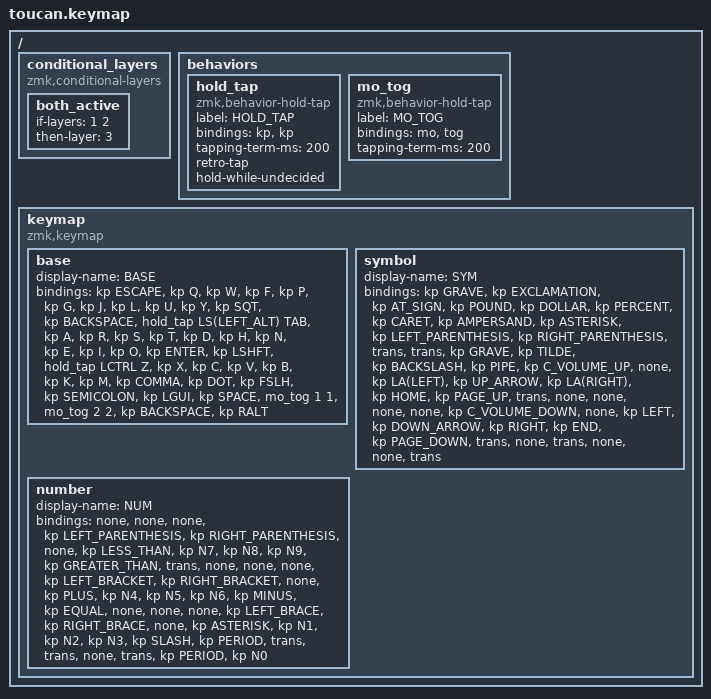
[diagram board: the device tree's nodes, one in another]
#include <behaviors.dtsi>
#include <dt-bindings/zmk/keys.h>

#define BASE 0
#define NAV  1
#define SYM  2
#define ADJ  3

/ {
    conditional_layers {
        compatible = "zmk,conditional-layers";

        both_active {
            if-layers = <1 2>;
            then-layer = <3>;
        };
    };

    behaviors {
        hold_tap: hold_tap {
            compatible = "zmk,behavior-hold-tap";
            label = "HOLD_TAP";
            bindings = <&kp>, <&kp>;

            #binding-cells = <2>;
            tapping-term-ms = <200>;
            retro-tap;
            hold-while-undecided;
        };

        mo_tog: mo_tog {
            compatible = "zmk,behavior-hold-tap";
            label = "MO_TOG";
            bindings = <&mo>, <&tog>;

            #binding-cells = <2>;
            tapping-term-ms = <200>;
        };
    };

    keymap {
        compatible = "zmk,keymap";

        base {
            display-name = "BASE";
            bindings = <
&kp ESCAPE  &kp Q  &kp W  &kp F  &kp P  &kp G  &kp J  &kp L  &kp U  &kp Y  &kp SQT  &kp BACKSPACE  &hold_tap LS(LEFT_ALT) TAB  &kp A  &kp R  &kp S  &kp T  &kp D  &kp H  &kp N  &kp E  &kp I  &kp O  &kp ENTER  &kp LSHFT  &hold_tap LCTRL Z  &kp X  &kp C  &kp V  &kp B  &kp K  &kp M  &kp COMMA  &kp DOT  &kp FSLH  &kp SEMICOLON  &kp LGUI  &kp SPACE  &mo_tog 1 1  &mo_tog 2 2  &kp BACKSPACE  &kp RALT
            >;
        };

        symbol {
            display-name = "SYM";
            bindings = <
&kp GRAVE  &kp EXCLAMATION  &kp AT_SIGN  &kp POUND  &kp DOLLAR  &kp PERCENT  &kp CARET  &kp AMPERSAND  &kp ASTERISK  &kp LEFT_PARENTHESIS  &kp RIGHT_PARENTHESIS  &trans  &trans  &kp GRAVE  &kp TILDE  &kp BACKSLASH  &kp PIPE  &kp C_VOLUME_UP  &none  &kp LA(LEFT)  &kp UP_ARROW  &kp LA(RIGHT)  &kp HOME  &kp PAGE_UP  &trans  &none  &none  &none  &none  &kp C_VOLUME_DOWN  &none  &kp LEFT  &kp DOWN_ARROW  &kp RIGHT  &kp END  &kp PAGE_DOWN  &trans  &none  &trans  &none  &none  &trans
            >;
        };

        number {
            display-name = "NUM";
            bindings = <
&none  &none  &none  &kp LEFT_PARENTHESIS  &kp RIGHT_PARENTHESIS  &none  &kp LESS_THAN  &kp N7  &kp N8  &kp N9  &kp GREATER_THAN  &trans  &none  &none  &none  &kp LEFT_BRACKET  &kp RIGHT_BRACKET  &none  &kp PLUS  &kp N4  &kp N5  &kp N6  &kp MINUS  &kp EQUAL  &none  &none  &none  &kp LEFT_BRACE  &kp RIGHT_BRACE  &none  &kp ASTERISK  &kp N1  &kp N2  &kp N3  &kp SLASH  &kp PERIOD  &trans  &trans  &none  &trans  &kp PERIOD  &kp N0
            >;
        };
    };
};
